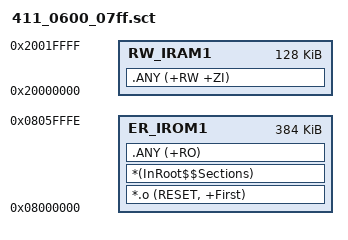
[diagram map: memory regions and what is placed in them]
; *************************************************************
; *** Scatter-Loading Description File generated by uVision ***
; *************************************************************
; 060000 - 07FFFF cut for ext memory
LR_IROM1 0x08000000 0x0005FFFF  {    ; load region size_region
  ER_IROM1 0x08000000 0x0005FFFF  {  ; load address = execution address
   *.o (RESET, +First)
   *(InRoot$$Sections)
   .ANY (+RO)
  }
  RW_IRAM1 0x20000000 0x00020000  {  ; RW data
   .ANY (+RW +ZI)
  }
}

